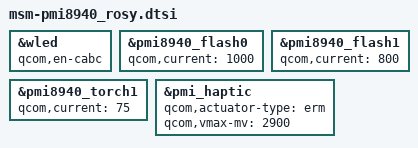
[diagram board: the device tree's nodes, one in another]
&wled {
	qcom,en-cabc;
};

&pmi8940_flash0 {
	qcom,current = <1000>;
};

&pmi8940_flash1 {
	qcom,current = <800>;
};

&pmi8940_torch1 {
	qcom,current = <75>;
};

&pmi_haptic {
	/delete-property/ qcom,en-brake;
	qcom,actuator-type = "erm";
	qcom,vmax-mv = <2900>;
};
